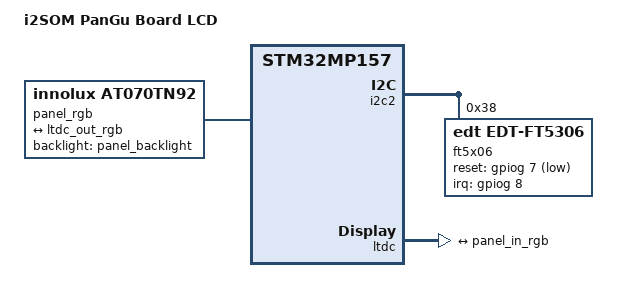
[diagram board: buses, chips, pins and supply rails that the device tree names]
// SPDX-License-Identifier: (GPL-2.0+ OR BSD-3-Clause)
/*
 * Copyright (C) i2SOM 2018 - All Rights Reserved
 * Author: Steve Chen <steve.chen@i2som.tech>.
 */

/dts-v1/;

#include "stm32mp157a-panguboard.dts"

/ {
	model = "i2SOM PanGu Board LCD";
	compatible = "i2som,pangu", "st,stm32mp157";

	panel_rgb: panel-rgb {
		compatible = "innolux,at070tn92";
		pinctrl-names = "default", "sleep";
		pinctrl-0 = <&ltdc_pins_b>;
		pinctrl-1 = <&ltdc_pins_sleep_b>;
		backlight = <&panel_backlight>;
		status = "okay";

		port {
			panel_in_rgb: endpoint {
				remote-endpoint = <&ltdc_out_rgb>;
			};
		};
	};

};

&i2c2 {
	ft5x06: ft5x06@38 {
		compatible = "edt,edt-ft5306";
		reg = <0x38>;
		interrupts = <8 IRQ_TYPE_EDGE_FALLING>;
		interrupt-parent = <&gpiog>;
		interrupt-controller;
		reset-gpios = <&gpiog 7 GPIO_ACTIVE_LOW>;
		status = "okay";
	};
};

&hdmi {
	status = "disabled";
};

&ltdc {
	status = "okay";

	port {
		#address-cells = <1>;
		#size-cells = <0>;

		ltdc_out_rgb: endpoint@1 {
			reg = <1>;
			remote-endpoint = <&panel_in_rgb>;
		};

	};
};
